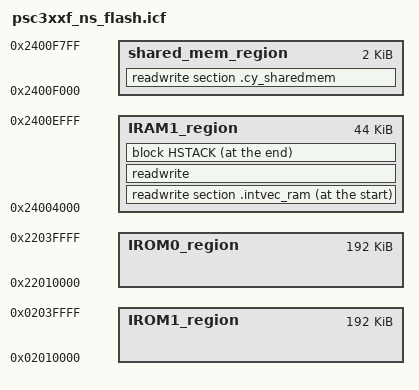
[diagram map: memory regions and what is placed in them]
/*******************************************************************************
* \file psc3xxf_ns_flash.icf
* \version 1.000
*
* Linker file for the IAR compiler.
*
* The main purpose of the linker script is to describe how the sections in the
* input files should be mapped into the output file, and to control the memory
* layout of the output file.
*
* \note The entry point is fixed and starts at 0x02010000. The valid application
* image should be placed there.
*
* \note The linker files included with the PDL template projects must be generic
* and handle all common use cases. Your project may not use every section
* defined in the linker files. In that case you may see warnings during the
* build process. In your project, you can simply comment out or remove the
* relevant code in the linker file.
*
********************************************************************************
* \copyright
* Copyright (c) (2020-2024), Cypress Semiconductor Corporation (an Infineon company) or
* an affiliate of Cypress Semiconductor Corporation.
* SPDX-License-Identifier: Apache-2.0
*
* Licensed under the Apache License, Version 2.0 (the "License");
* you may not use this file except in compliance with the License.
* You may obtain a copy of the License at
*
*     http://www.apache.org/licenses/LICENSE-2.0
*
* Unless required by applicable law or agreed to in writing, software
* distributed under the License is distributed on an "AS IS" BASIS,
* WITHOUT WARRANTIES OR CONDITIONS OF ANY KIND, either express or implied.
* See the License for the specific language governing permissions and
* limitations under the License.
*******************************************************************************/

/*###ICF### Section handled by ICF editor, don't touch! ****/
/*-Editor annotation file-*/
/* IcfEditorFile="$TOOLKIT_DIR$\config\ide\IcfEditor\cortex_v1_4.xml" */
/*-Specials-*/
define symbol __ICFEDIT_intvec_start__ = 0x00000000;

/* The symbols below define the location and size of blocks of memory in the target.
 * Use these symbols to specify the memory regions available for allocation.
 */
/* RAM */
define symbol __size_sram__          = 0x00010000;
if (!isdefinedsymbol(_size_S_SRAM)) {
    define symbol __size_data_s_sram__ = 0x00004000;
} else {
  define symbol __size_data_s_sram__ = _size_S_SRAM;
}
define symbol __size_sram_s_shm__    = 0x00000800;
define symbol __size_sram_ns_shm__   = 0x00000800;
define symbol __size_data_ns_sram__  = __size_sram__ - __size_data_s_sram__ - __size_sram_s_shm__ - __size_sram_ns_shm__;

define symbol __ICFEDIT_region_IRAM1_start__   = 0x24000000 + __size_data_s_sram__;
define symbol __ICFEDIT_region_IRAM1_size__       = 0x0000B000; /* __size_data_ns_sram__ */
define symbol __ICFEDIT_region_SHARED_MEM_start__ = 0x24000000 + __size_data_s_sram__ + __size_data_ns_sram__;
define symbol __ICFEDIT_region_SHARED_MEM_size__  = 0x00000800; /* __size_sram_ns_shm__ */

/* Flash */
define symbol __size_flash__        = 0x00040000;
if (!isdefinedsymbol(_size_S_FLASH)) {
    define symbol __size_s_flash__ = 0x00010000;
} else {
  define symbol __size_s_flash__ = _size_S_FLASH;
}
define symbol __size_ns_flash__     = __size_flash__ - __size_s_flash__;

define symbol __ICFEDIT_region_IROM0_start__  = 0x22000000 + __size_s_flash__; /* flash sbus */
define symbol __ICFEDIT_region_IROM1_start__  = 0x02000000 + __size_s_flash__; /* cbus */
define symbol __ICFEDIT_region_IROM1_size__   = __size_ns_flash__; /* __size_ns_flash__ */

/*-Sizes-*/
if (!isdefinedsymbol(__STACK_SIZE)) {
  define symbol __ICFEDIT_size_cstack__ = 0x1000;
} else {
  define symbol __ICFEDIT_size_cstack__ = __STACK_SIZE;
}
define symbol __ICFEDIT_size_proc_stack__ = 0x0;

/* Defines the minimum heap size. The actual heap size will be expanded to the end of the stack region */
if (!isdefinedsymbol(__HEAP_SIZE)) {
    define symbol __ICFEDIT_size_heap__ = 0x0400;
} else {
  define symbol __ICFEDIT_size_heap__ = __HEAP_SIZE;
}
/**** End of ICF editor section. ###ICF###*/

/* The size of the MCU boot header area at the start of FLASH */
define symbol BOOT_HEADER_SIZE  = 0x0;

define memory mem with size = 4G;
define region IROM0_region = mem:[from __ICFEDIT_region_IROM0_start__ size __ICFEDIT_region_IROM1_size__];
define region IROM1_region = mem:[from __ICFEDIT_region_IROM1_start__ size __ICFEDIT_region_IROM1_size__];
define region IRAM1_region = mem:[from __ICFEDIT_region_IRAM1_start__ size __ICFEDIT_region_IRAM1_size__];
define region shared_mem_region =  mem:[from __ICFEDIT_region_SHARED_MEM_start__ size __ICFEDIT_region_SHARED_MEM_size__]; /* shared_ram0 */
logical [from __ICFEDIT_region_IROM1_start__ size __ICFEDIT_region_IROM1_size__] =
physical [from __ICFEDIT_region_IROM0_start__ size __ICFEDIT_region_IROM1_size__]; /* logical 0x02000000 == physical 0x22000000 */

define block CSTACK     with alignment = 8, size = __ICFEDIT_size_cstack__     { };
define block PROC_STACK with alignment = 8, size = __ICFEDIT_size_proc_stack__ { };
define block HEAP       with expanding size, alignment = 8, minimum size = __ICFEDIT_size_heap__ { };
define block HSTACK {block HEAP, block PROC_STACK, last block CSTACK};
define block RO     {first section .intvec, readonly};

/*-Initializations-*/
initialize by copy { readwrite };
do not initialize  { section .noinit, section .intvec_ram };

/*-Placement-*/

/* Flash - Cortex-M33 application */
place at address (__ICFEDIT_region_IROM1_start__ + BOOT_HEADER_SIZE) { block RO };

/* RAM */
place at start of IRAM1_region  { readwrite section .intvec_ram};
place in          IRAM1_region  { readwrite };
place at end   of IRAM1_region  { block HSTACK };

place in          shared_mem_region { readwrite section .cy_sharedmem };

keep {  section .intvec  };

/* EOF */
